# N570F064_v4_2 register map
File version: 1.0
Registers are 32-bit, read-write, reset 0x0 unless marked. A register's access mark holds for its fields unless they carry their own. Offsets are from the block's base; [hi:lo] are bit positions; {n}, {i} and the like mark numbered series.

## RTC — RTC Register Map
Base 0x40008000
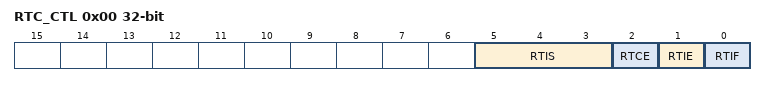
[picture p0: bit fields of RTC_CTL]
0x00 RTC_CTL — RTC Control Register
  [5:3] RTIS — RTC Timer Interval Select. These two bits select the timeout interval for the RTC.
    0=Time-out frequency is 0.25Hz,; 1=Time-out frequency is 0.5Hz,; 2=Time-out frequency is 1Hz,; 3=Time-out frequency is 2Hz; 4=Time-out frequency is 4Hz,; 5=Time-out frequency is 8Hz,; 6=Time-out frequency is 16Hz,; 7=Time-out frequency is 32Hz
  [2] RTCE — RTC Enable
    0=Disable RTC function; 1=Enable RTC function
  [1] RTIE — RTC Interrupt Enable
    0=Disable the RTC interrupt; 1=Enable the RTC interrupt
  [0] RTIF — RTC Interrupt Flag. If the RTC interrupt is enabled, then the hardware will set this bit to indicate that the RTC interrupt has occurred. If the RTC interrupt is not enabled, then this bit indicates that a timeout period has elapsed. Note: This bit is cleared by writing 1 to this bit.
    0=RTC interrupt does not occur; 1=RTC interrupt occurs

## OSCFM — OSCFM Register Map
Base 0x40008004
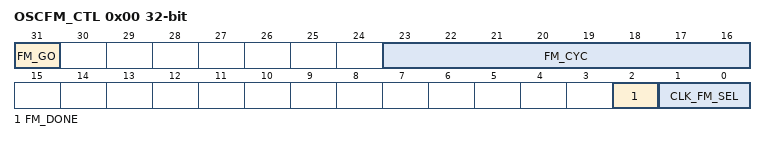
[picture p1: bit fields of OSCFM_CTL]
0x00 OSCFM_CTL — Frequency Measurement Control Register
  [31] FM_GO — FM GO BUSY. 0 --- no action. 1 --- start to frequency measurement
  [23:16] FM_CYC — FM Cycle number. Note: OSCFM_CYC[7:0] also can write this resigster
  [2] FM_DONE — FM DONE FLAG. If FM_GO is "0", clear the FM_DONE.
    0=not done or no action; 1=testing done,
  [1:0] CLK_FM_SEL — CLK FM SELETION
0x04 OSCFM_CNT ro — Frequency Measurement Counter Register
  [15:0] OSCFM_CNT — FM Counter Number. Report the counter
0x08 OSCFM_CYCLE — Frequency Measurement Cycle Register
  [15:0] FM_CYC — FM iteration cycle number . Note: FM_CYC[7:0] can be overwritten by OSCFM_CTL[23:16]

## TMR — TMR Register Map
Base 0x40010000
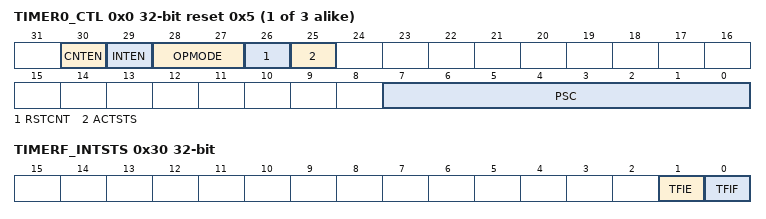
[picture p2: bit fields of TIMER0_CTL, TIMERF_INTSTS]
{0x0+0x20*i} TIMER{i}_CTL reset 0x5 (i=0..2) — Timer{i} Control and Status Register
  [30] CNTEN — Counter Enable Bit
    0=Stop/Suspend counting; 1=Start counting
  [29] INTEN — Interrupt Enable Bit. If timer interrupt is enabled, the timer asserts its interrupt signal when the associated count is equal to TIMERx_CMP.
    0=Disable TIMER Interrupt; 1=Enable TIMER Interrupt
  [28:27] OPMODE — Timer Operating Mode
    0=The Timer is operating in the one-shot mode. The associated interrupt signal is generated once (if INTEN is 1) and CNTEN is automatically cleared by hardware; 1=The Timer is operating in the periodic mode. The associated interrupt signal is generated periodically (if INTEN is 1); 3=The Timer is operating in continuous counting mode. The associated interrupt signal is generated when TIMERx_CNT = TIMERx_CMP (if INTEN is 1); however, the 16-bit up-counter counts continuously without reset
  [26] RSTCNT — Counter Reset Bit. Set this bit will reset the Timer counter, pre-scale and also force CNTEN to 0.
    0=No effect; 1=Reset Timer's pre-scale counter, internal 16-bit up-counter and CNTEN bit
  [25] ACTSTS ro — Timer Active Status Bit (Read Only). This bit indicates the counter status of Timer.
    0=Timer is not active; 1=Timer is active
  [7:0] PSC — Timer Clock Prescaler
{0x4+0x20*i} TIMER{i}_CMP (i=0..2) — Timer{i} Compare Register
  [15:0] CMPDAT — Timer Comparison Value. Note 1: Never set CMPDAT to 0x000 or 0x001. Timer will not function correctly. Note 2: No matter CNTEN is 0 or 1, whenever software writes a new value into this register, TIMER will restart counting by using this new value and abort previous count.
{0x8+0x20*i} TIMER{i}_INTSTS (i=0..2) — Timer{i} Interrupt Status Register
  [0] TIF ro — Timer Interrupt Flag (Read Only). This bit indicates the interrupt status of Timer. TIF bit is set by hardware when the 16-bit counter matches the timer comparison value (CMPDAT). It is cleared by writing 1 to itself
    0=No effect; 1=CNT (TIMERx_CNT[15:0]) value matches the CMPDAT (TIMERx_CMP[15:0]) value
{0xC+0x20*i} TIMER{i}_CNT ro (i=0..2) — Timer{i} Data Register
  [15:0] CNT — Timer Data Register. User can read this register for the current up-counter value while TIMERx_CTL.CNTEN is set to 1,
0x30 TIMERF_INTSTS — TimerF Interrupt Status Register
  [1] TFIE — TimerF Interrupt Enable
    0=Disable TimerF Interrupt; 1=Enable TimerF Interrupt
  [0] TFIF — TimerF Interrupt Flag. This bit indicates the interrupt status of TimerF. TFIF bit is set by hardware when TimerF time out. It is cleared by writing 1 to this bit.
    0=It indicates that TimerF does not time out yet; 1=It indicates that TimerF time out. The interrupt flag is set if TimerF interrupt was enabled
0x34 IR_CTL — IR Carrier Output Control Register
